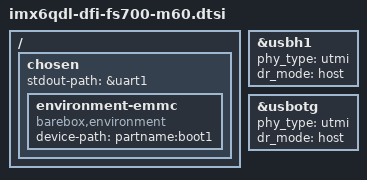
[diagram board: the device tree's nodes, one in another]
#include <arm/nxp/imx/imx6qdl-dfi-fs700-m60.dtsi>

/ {
	chosen {
		stdout-path = &uart1;

		environment-emmc {
			compatible = "barebox,environment";
			device-path = &usdhc4, "partname:boot1";
		};
	};
};

&usbh1 {
	phy_type = "utmi";
	dr_mode = "host";
};

&usbotg {
	phy_type = "utmi";
	dr_mode = "host";
};
